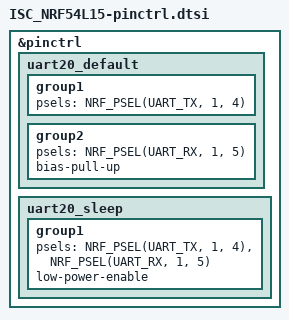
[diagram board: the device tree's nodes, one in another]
&pinctrl {
     uart20_default: uart20_default {
        group1 {
            psels = <NRF_PSEL(UART_TX, 1, 4)>;
        };
        group2 {
            psels = <NRF_PSEL(UART_RX, 1, 5)>;
            bias-pull-up;
        };
    };

    uart20_sleep: uart20_sleep {
        group1 {
            psels = <NRF_PSEL(UART_TX, 1, 4)>,
                    <NRF_PSEL(UART_RX, 1, 5)>;
            low-power-enable;
        };
    };
};
